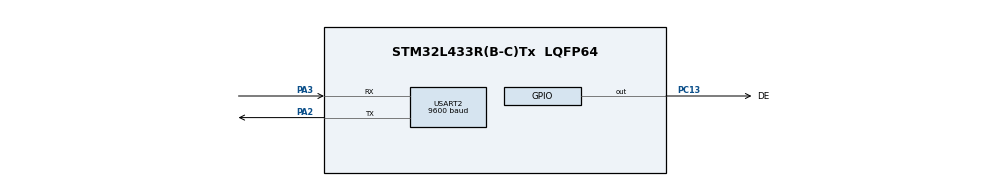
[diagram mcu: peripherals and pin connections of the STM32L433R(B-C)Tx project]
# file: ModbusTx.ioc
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Mcu.Family=STM32L4
Mcu.Name=STM32L433R(B-C)Tx
Mcu.Package=LQFP64
NVIC.PriorityGroup=NVIC_PRIORITYGROUP_4
PA2.Mode=Asynchronous
PA2.Signal=USART2_TX
PA3.Mode=Asynchronous
PA3.Signal=USART2_RX
PC13.GPIO_Label=DE
PC13.Signal=GPIO_Output
ProjectManager.HeapSize=0x200
ProjectManager.StackSize=0x400
ProjectManager.TargetToolchain=STM32CubeIDE
RCC.HSE_VALUE=8000000
RCC.HSI48_VALUE=48000000
RCC.HSI_VALUE=16000000
RCC.LSE_VALUE=32768
RCC.MSI_VALUE=4000000
RCC.VCOOutputFreq_Value=32000000
USART2.BaudRate=9600
USART2.OverrunDisableParam=ADVFEATURE_OVERRUN_DISABLE
USART2.Parity=PARITY_EVEN
USART2.SwapParam=ADVFEATURE_SWAP_ENABLE
USART2.TxPinLevelInvertParam=ADVFEATURE_TXINV_DISABLE
USART2.VirtualMode-Asynchronous=VM_ASYNC
USART2.WordLength=WORDLENGTH_9B
board=custom

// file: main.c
/* USER CODE BEGIN Header */
/**
  ******************************************************************************
  * @file           : main.c
  * @brief          : Main program body
  ******************************************************************************
  * @attention
  *
  * Copyright (c) 2026 STMicroelectronics.
  * All rights reserved.
  *
  * This software is licensed under terms that can be found in the LICENSE file
  * in the root directory of this software component.
  * If no LICENSE file comes with this software, it is provided AS-IS.
  *
  ******************************************************************************
  */
/* USER CODE END Header */
#include "main.h"

UART_HandleTypeDef huart2;

void SystemClock_Config(void);
static void MX_GPIO_Init(void);
static void MX_USART2_UART_Init(void);

/* USER CODE BEGIN 0 */
uint16_t Modbus_CRC16(uint8_t *buf, uint16_t len)
{
    uint16_t crc = 0xFFFF;
    for (uint16_t i = 0; i < len; i++)
    {
        crc ^= buf[i];
        for (uint8_t j = 0; j < 8; j++)
        {
            if (crc & 1) crc = (crc >> 1) ^ 0xA001;
            else         crc >>= 1;
        }
    }
    return crc;
}

void Modbus_Send(uint8_t *data, uint16_t len)
{
    uint16_t crc = Modbus_CRC16(data, len);
    data[len]     = crc & 0xFF;   /* CRC low byte first */
    data[len + 1] = crc >> 8;

    HAL_GPIO_WritePin(DE_GPIO_Port, DE_Pin, GPIO_PIN_SET);    /* transmit */
    HAL_UART_Transmit(&huart2, data, len + 2, 100);
    while (__HAL_UART_GET_FLAG(&huart2, UART_FLAG_TC) == RESET);
    HAL_GPIO_WritePin(DE_GPIO_Port, DE_Pin, GPIO_PIN_RESET);  /* receive */
}
/* USER CODE END 0 */

int main(void)
{

  /* MCU Configuration--------------------------------------------------------*/

  /* Reset of all peripherals, Initializes the Flash interface and the Systick. */
  HAL_Init();

  /* Configure the system clock */
  SystemClock_Config();

  /* Initialize all configured peripherals */
  MX_GPIO_Init();
  MX_USART2_UART_Init();
  /* USER CODE BEGIN 2 */
  uint8_t frame[8] = {0x01, 0x03, 0x00, 0x00, 0x00, 0x02};
  /* USER CODE END 2 */

  /* Infinite loop */
  while (1)
  {

    /* USER CODE BEGIN 3 */
	  Modbus_Send(frame, 6);
	  HAL_Delay(1000);
  }
  /* USER CODE END 3 */
}

void SystemClock_Config(void)
{
  RCC_OscInitTypeDef RCC_OscInitStruct = {0};
  RCC_ClkInitTypeDef RCC_ClkInitStruct = {0};

  /** Configure the main internal regulator output voltage
  */
  if (HAL_PWREx_ControlVoltageScaling(PWR_REGULATOR_VOLTAGE_SCALE1) != HAL_OK)
  {
    Error_Handler();
  }

  /** Initializes the RCC Oscillators according to the specified parameters
  * in the RCC_OscInitTypeDef structure.
  */
  RCC_OscInitStruct.OscillatorType = RCC_OSCILLATORTYPE_MSI;
  RCC_OscInitStruct.MSIState = RCC_MSI_ON;
  RCC_OscInitStruct.MSICalibrationValue = 0;
  RCC_OscInitStruct.MSIClockRange = RCC_MSIRANGE_6;
  RCC_OscInitStruct.PLL.PLLState = RCC_PLL_NONE;
  if (HAL_RCC_OscConfig(&RCC_OscInitStruct) != HAL_OK)
  {
    Error_Handler();
  }

  /** Initializes the CPU, AHB and APB buses clocks
  */
  RCC_ClkInitStruct.ClockType = RCC_CLOCKTYPE_HCLK|RCC_CLOCKTYPE_SYSCLK
                              |RCC_CLOCKTYPE_PCLK1|RCC_CLOCKTYPE_PCLK2;
  RCC_ClkInitStruct.SYSCLKSource = RCC_SYSCLKSOURCE_MSI;
  RCC_ClkInitStruct.AHBCLKDivider = RCC_SYSCLK_DIV1;
  RCC_ClkInitStruct.APB1CLKDivider = RCC_HCLK_DIV1;
  RCC_ClkInitStruct.APB2CLKDivider = RCC_HCLK_DIV1;

  if (HAL_RCC_ClockConfig(&RCC_ClkInitStruct, FLASH_LATENCY_0) != HAL_OK)
  {
    Error_Handler();
  }
}

static void MX_USART2_UART_Init(void)
{

  huart2.Instance = USART2;
  huart2.Init.BaudRate = 9600;
  huart2.Init.WordLength = UART_WORDLENGTH_9B;
  huart2.Init.StopBits = UART_STOPBITS_1;
  huart2.Init.Parity = UART_PARITY_EVEN;
  huart2.Init.Mode = UART_MODE_TX_RX;
  huart2.Init.HwFlowCtl = UART_HWCONTROL_NONE;
  huart2.Init.OverSampling = UART_OVERSAMPLING_16;
  huart2.Init.OneBitSampling = UART_ONE_BIT_SAMPLE_DISABLE;
  huart2.AdvancedInit.AdvFeatureInit = UART_ADVFEATURE_SWAP_INIT|UART_ADVFEATURE_RXOVERRUNDISABLE_INIT;
  huart2.AdvancedInit.Swap = UART_ADVFEATURE_SWAP_ENABLE;
  huart2.AdvancedInit.OverrunDisable = UART_ADVFEATURE_OVERRUN_DISABLE;
  if (HAL_UART_Init(&huart2) != HAL_OK)
  {
    Error_Handler();
  }

}

static void MX_GPIO_Init(void)
{
  GPIO_InitTypeDef GPIO_InitStruct = {0};

  /* GPIO Ports Clock Enable */
  __HAL_RCC_GPIOC_CLK_ENABLE();
  __HAL_RCC_GPIOA_CLK_ENABLE();

  /*Configure GPIO pin Output Level */
  HAL_GPIO_WritePin(DE_GPIO_Port, DE_Pin, GPIO_PIN_RESET);

  /*Configure GPIO pin : DE_Pin */
  GPIO_InitStruct.Pin = DE_Pin;
  GPIO_InitStruct.Mode = GPIO_MODE_OUTPUT_PP;
  GPIO_InitStruct.Pull = GPIO_NOPULL;
  GPIO_InitStruct.Speed = GPIO_SPEED_FREQ_LOW;
  HAL_GPIO_Init(DE_GPIO_Port, &GPIO_InitStruct);

}

void Error_Handler(void)
{
  __disable_irq();
  while (1)
  {
  }
}
